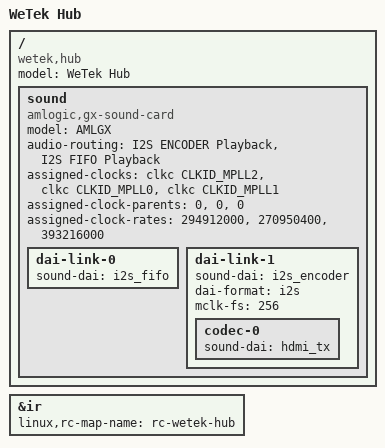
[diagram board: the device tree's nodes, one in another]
// SPDX-License-Identifier: (GPL-2.0+ OR MIT)
/*
 * Copyright (c) 2016 BayLibre, Inc.
 * Author: Neil Armstrong <narmstrong@baylibre.com>
 */

/dts-v1/;

#include "meson-gxbb-wetek.dtsi"

/ {
	compatible = "wetek,hub", "amlogic,meson-gxbb";
	model = "WeTek Hub";

	sound {
		compatible = "amlogic,gx-sound-card";
		model = "AMLGX";
		audio-routing = "I2S ENCODER Playback", "I2S FIFO Playback";

		assigned-clocks = <&clkc CLKID_MPLL2>,
				  <&clkc CLKID_MPLL0>,
				  <&clkc CLKID_MPLL1>;
		assigned-clock-parents = <0>, <0>, <0>;
		assigned-clock-rates = <294912000>,
				       <270950400>,
				       <393216000>;
		status = "okay";

		dai-link-0 {
			sound-dai = <&i2s_fifo>;
		};

		dai-link-1 {
			sound-dai = <&i2s_encoder>;
			dai-format = "i2s";
			mclk-fs = <256>;

			codec-0 {
				sound-dai = <&hdmi_tx>;
			};
		};
	};
};

&ir {
	linux,rc-map-name = "rc-wetek-hub";
};
